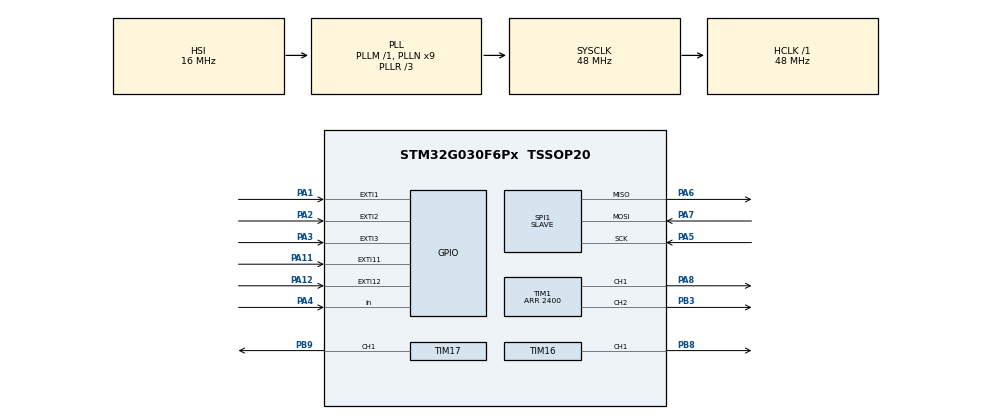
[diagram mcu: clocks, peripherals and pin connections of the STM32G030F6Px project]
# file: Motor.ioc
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Dma.Request0=TIM1_CH1
Dma.Request1=SPI1_RX
Dma.Request2=SPI1_TX
Dma.SPI1_RX.1.Direction=DMA_PERIPH_TO_MEMORY
Dma.SPI1_RX.1.EventEnable=DISABLE
Dma.SPI1_RX.1.Instance=DMA1_Channel1
Dma.SPI1_RX.1.MemDataAlignment=DMA_MDATAALIGN_HALFWORD
Dma.SPI1_RX.1.MemInc=DMA_MINC_ENABLE
Dma.SPI1_RX.1.Mode=DMA_NORMAL
Dma.SPI1_RX.1.PeriphDataAlignment=DMA_PDATAALIGN_HALFWORD
Dma.SPI1_RX.1.PeriphInc=DMA_PINC_DISABLE
Dma.SPI1_RX.1.Polarity=HAL_DMAMUX_REQ_GEN_RISING
Dma.SPI1_RX.1.Priority=DMA_PRIORITY_MEDIUM
Dma.SPI1_RX.1.RequestNumber=1
Dma.SPI1_RX.1.SignalID=NONE
Dma.SPI1_RX.1.SyncEnable=DISABLE
Dma.SPI1_RX.1.SyncPolarity=HAL_DMAMUX_SYNC_NO_EVENT
Dma.SPI1_RX.1.SyncRequestNumber=1
Dma.SPI1_RX.1.SyncSignalID=NONE
Dma.SPI1_TX.2.Direction=DMA_MEMORY_TO_PERIPH
Dma.SPI1_TX.2.EventEnable=DISABLE
Dma.SPI1_TX.2.Instance=DMA1_Channel2
Dma.SPI1_TX.2.MemDataAlignment=DMA_MDATAALIGN_HALFWORD
Dma.SPI1_TX.2.MemInc=DMA_MINC_ENABLE
Dma.SPI1_TX.2.Mode=DMA_NORMAL
Dma.SPI1_TX.2.PeriphDataAlignment=DMA_PDATAALIGN_HALFWORD
Dma.SPI1_TX.2.PeriphInc=DMA_PINC_DISABLE
Dma.SPI1_TX.2.Polarity=HAL_DMAMUX_REQ_GEN_RISING
Dma.SPI1_TX.2.Priority=DMA_PRIORITY_MEDIUM
Dma.SPI1_TX.2.RequestNumber=1
Dma.SPI1_TX.2.SignalID=NONE
Dma.SPI1_TX.2.SyncEnable=DISABLE
Dma.SPI1_TX.2.SyncPolarity=HAL_DMAMUX_SYNC_NO_EVENT
Dma.SPI1_TX.2.SyncRequestNumber=1
Dma.SPI1_TX.2.SyncSignalID=NONE
Dma.TIM1_CH1.0.Direction=DMA_MEMORY_TO_PERIPH
Dma.TIM1_CH1.0.EventEnable=DISABLE
Dma.TIM1_CH1.0.Instance=DMA1_Channel4
Dma.TIM1_CH1.0.MemDataAlignment=DMA_MDATAALIGN_BYTE
Dma.TIM1_CH1.0.MemInc=DMA_MINC_ENABLE
Dma.TIM1_CH1.0.Mode=DMA_CIRCULAR
Dma.TIM1_CH1.0.PeriphDataAlignment=DMA_PDATAALIGN_HALFWORD
Dma.TIM1_CH1.0.PeriphInc=DMA_PINC_DISABLE
Dma.TIM1_CH1.0.Polarity=HAL_DMAMUX_REQ_GEN_RISING
Dma.TIM1_CH1.0.Priority=DMA_PRIORITY_LOW
Dma.TIM1_CH1.0.RequestNumber=1
Dma.TIM1_CH1.0.SignalID=NONE
Dma.TIM1_CH1.0.SyncEnable=DISABLE
Dma.TIM1_CH1.0.SyncPolarity=HAL_DMAMUX_SYNC_NO_EVENT
Dma.TIM1_CH1.0.SyncRequestNumber=1
Dma.TIM1_CH1.0.SyncSignalID=NONE
Mcu.Family=STM32G0
Mcu.Name=STM32G030F6Px
Mcu.Package=TSSOP20
NVIC.DMA1_Ch4_5_DMAMUX1_OVR_IRQn=true\:2\:0\:true\:false\:true\:false\:true\:true
NVIC.DMA1_Channel1_IRQn=true\:0\:0\:true\:false\:true\:false\:true\:true
NVIC.DMA1_Channel2_3_IRQn=true\:0\:0\:true\:false\:true\:false\:true\:true
NVIC.EXTI0_1_IRQn=true\:0\:0\:true\:false\:true\:true\:true\:true
NVIC.EXTI2_3_IRQn=true\:1\:0\:true\:false\:true\:true\:true\:true
NVIC.EXTI4_15_IRQn=true\:1\:0\:true\:false\:true\:true\:true\:true
NVIC.TIM1_BRK_UP_TRG_COM_IRQn=true\:2\:0\:true\:false\:true\:true\:true\:true
NVIC.TIM3_IRQn=true\:3\:0\:true\:false\:true\:true\:true\:true
PA1.Signal=GPXTI1
PA11\ [PA9].Signal=GPXTI11
PA12\ [PA10].Signal=GPXTI12
PA13.Mode=Serial_Wire
PA13.Signal=SYS_SWDIO
PA14-BOOT0.Mode=Serial_Wire
PA14-BOOT0.Signal=SYS_SWCLK
PA14-BOOT0__PA15.StandardMode=true
PA2.Signal=GPXTI2
PA3.Signal=GPXTI3
PA4.Signal=GPIO_Input
PA5.Mode=Full_Duplex_Slave
PA5.Signal=SPI1_SCK
PA6.Mode=Full_Duplex_Slave
PA6.Signal=SPI1_MISO
PA7.Mode=Full_Duplex_Slave
PA7.Signal=SPI1_MOSI
PA8.Signal=S_TIM1_CH1
PB0__PB1__PB2__PA8.StandardMode=true
PB3.Signal=S_TIM1_CH2
PB3__PB4__PB5__PB6.StandardMode=true
PB7__PB8.StandardMode=true
PB8.Signal=S_TIM16_CH1
PB9.Signal=S_TIM17_CH1
PC14-OSC32_IN\ (PC14)__PB9.StandardMode=true
ProjectManager.HeapSize=0x200
ProjectManager.StackSize=0x400
ProjectManager.TargetToolchain=STM32CubeIDE
RCC.ADCFreq_Value=48000000
RCC.AHBFreq_Value=48000000
RCC.CortexFreq_Value=48000000
RCC.EXTERNAL_CLOCK_VALUE=12288000
RCC.HCLKFreq_Value=48000000
RCC.HSE_VALUE=8000000
RCC.HSI_VALUE=16000000
RCC.LSE_VALUE=32768
RCC.PLLN=9
RCC.PLLP=RCC_PLLP_DIV32
RCC.PLLR=RCC_PLLR_DIV3
RCC.SYSCLKFreq_VALUE=48000000
RCC.SYSCLKSource=RCC_SYSCLKSOURCE_PLLCLK
RCC.VCOOutputFreq_Value=144000000
SH.S_TIM16_CH1.0=TIM16_CH1,PWM Generation1 CH1
SH.S_TIM17_CH1.0=TIM17_CH1,PWM Generation1 CH1
SH.S_TIM1_CH1.0=TIM1_CH1,PWM Generation1 CH1
SH.S_TIM1_CH2.0=TIM1_CH2,PWM Generation2 CH2
SPI1.CLKPolarity=SPI_POLARITY_LOW
SPI1.CRCCalculation=SPI_CRCCALCULATION_ENABLE
SPI1.CRCLength=SPI_CRC_LENGTH_DATASIZE
SPI1.DataSize=SPI_DATASIZE_16BIT
SPI1.Direction=SPI_DIRECTION_2LINES
SPI1.Mode=SPI_MODE_SLAVE
SPI1.VirtualType=VM_SLAVE
TIM1.AutoReloadPreload=TIM_AUTORELOAD_PRELOAD_ENABLE
TIM1.Channel-PWM\ Generation1\ CH1=TIM_CHANNEL_1
TIM1.Channel-PWM\ Generation2\ CH2=TIM_CHANNEL_2
TIM1.OCMode_PWM-PWM\ Generation1\ CH1=TIM_OCMODE_PWM1
TIM1.OCPolarity_1=TIM_OCPOLARITY_HIGH
TIM1.OCPolarity_2=TIM_OCPOLARITY_HIGH
TIM1.Period=2400
TIM16.Channel=TIM_CHANNEL_1
TIM16.Period=2400
TIM16.Prescaler=0
TIM17.Channel=TIM_CHANNEL_1
TIM17.Period=2400
TIM17.Prescaler=0
TIM3.AutoReloadPreload=TIM_AUTORELOAD_PRELOAD_ENABLE
TIM3.Period=2400
TIM3.Prescaler=0
TIM3.TIM_MasterOutputTrigger=TIM_TRGO_UPDATE
VP_CRC_VS_CRC.Mode=CRC_Activate
VP_TIM16_VS_ClockSourceINT.Mode=Enable_Timer
VP_TIM17_VS_ClockSourceINT.Mode=Enable_Timer
VP_TIM1_VS_ClockSourceINT.Mode=Internal
VP_TIM3_VS_ClockSourceINT.Mode=Internal
board=custom

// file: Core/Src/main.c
/* USER CODE BEGIN Header */
/**
  ******************************************************************************
  * @file           : main.c
  * @brief          : Main program body
  ******************************************************************************
  * @attention
  *
  * Copyright (c) 2024 STMicroelectronics.
  * All rights reserved.
  *
  * This software is licensed under terms that can be found in the LICENSE file
  * in the root directory of this software component.
  * If no LICENSE file comes with this software, it is provided AS-IS.
  *
  ******************************************************************************
  */
/* USER CODE END Header */
#include "main.h"

/* USER CODE BEGIN PD */
extern void boardInit();
extern void boardLoop();

/* USER CODE END PD */

CRC_HandleTypeDef hcrc;

SPI_HandleTypeDef hspi1;
DMA_HandleTypeDef hdma_spi1_rx;
DMA_HandleTypeDef hdma_spi1_tx;

TIM_HandleTypeDef htim1;
TIM_HandleTypeDef htim3;
TIM_HandleTypeDef htim16;
TIM_HandleTypeDef htim17;
DMA_HandleTypeDef hdma_tim1_ch1;

void SystemClock_Config(void);
static void MX_GPIO_Init(void);
static void MX_DMA_Init(void);
static void MX_SPI1_Init(void);
static void MX_TIM1_Init(void);
static void MX_TIM3_Init(void);
static void MX_CRC_Init(void);
static void MX_TIM16_Init(void);
static void MX_TIM17_Init(void);

int main(void)
{

  /* MCU Configuration--------------------------------------------------------*/

  /* Reset of all peripherals, Initializes the Flash interface and the Systick. */
  HAL_Init();

  /* Configure the system clock */
  SystemClock_Config();

  /* Initialize all configured peripherals */
  MX_GPIO_Init();
  MX_DMA_Init();
  MX_SPI1_Init();
  MX_TIM1_Init();
  MX_TIM3_Init();
  MX_CRC_Init();
  MX_TIM16_Init();
  MX_TIM17_Init();

  /* Infinite loop */
  /* USER CODE BEGIN WHILE */
  boardInit();
  while (1)
  {
    /* USER CODE END WHILE */

    /* USER CODE BEGIN 3 */
    boardLoop();
  }
  /* USER CODE END 3 */
}

void SystemClock_Config(void)
{
  RCC_OscInitTypeDef RCC_OscInitStruct = {0};
  RCC_ClkInitTypeDef RCC_ClkInitStruct = {0};

  /** Configure the main internal regulator output voltage
  */
  HAL_PWREx_ControlVoltageScaling(PWR_REGULATOR_VOLTAGE_SCALE1);

  /** Initializes the RCC Oscillators according to the specified parameters
  * in the RCC_OscInitTypeDef structure.
  */
  RCC_OscInitStruct.OscillatorType = RCC_OSCILLATORTYPE_HSI;
  RCC_OscInitStruct.HSIState = RCC_HSI_ON;
  RCC_OscInitStruct.HSIDiv = RCC_HSI_DIV1;
  RCC_OscInitStruct.HSICalibrationValue = RCC_HSICALIBRATION_DEFAULT;
  RCC_OscInitStruct.PLL.PLLState = RCC_PLL_ON;
  RCC_OscInitStruct.PLL.PLLSource = RCC_PLLSOURCE_HSI;
  RCC_OscInitStruct.PLL.PLLM = RCC_PLLM_DIV1;
  RCC_OscInitStruct.PLL.PLLN = 9;
  RCC_OscInitStruct.PLL.PLLP = RCC_PLLP_DIV32;
  RCC_OscInitStruct.PLL.PLLR = RCC_PLLR_DIV3;
  if (HAL_RCC_OscConfig(&RCC_OscInitStruct) != HAL_OK)
  {
    Error_Handler();
  }

  /** Initializes the CPU, AHB and APB buses clocks
  */
  RCC_ClkInitStruct.ClockType = RCC_CLOCKTYPE_HCLK|RCC_CLOCKTYPE_SYSCLK
                              |RCC_CLOCKTYPE_PCLK1;
  RCC_ClkInitStruct.SYSCLKSource = RCC_SYSCLKSOURCE_PLLCLK;
  RCC_ClkInitStruct.AHBCLKDivider = RCC_SYSCLK_DIV1;
  RCC_ClkInitStruct.APB1CLKDivider = RCC_HCLK_DIV1;

  if (HAL_RCC_ClockConfig(&RCC_ClkInitStruct, FLASH_LATENCY_1) != HAL_OK)
  {
    Error_Handler();
  }
}

static void MX_CRC_Init(void)
{

  hcrc.Instance = CRC;
  hcrc.Init.DefaultPolynomialUse = DEFAULT_POLYNOMIAL_ENABLE;
  hcrc.Init.DefaultInitValueUse = DEFAULT_INIT_VALUE_ENABLE;
  hcrc.Init.InputDataInversionMode = CRC_INPUTDATA_INVERSION_NONE;
  hcrc.Init.OutputDataInversionMode = CRC_OUTPUTDATA_INVERSION_DISABLE;
  hcrc.InputDataFormat = CRC_INPUTDATA_FORMAT_BYTES;
  if (HAL_CRC_Init(&hcrc) != HAL_OK)
  {
    Error_Handler();
  }

}

static void MX_SPI1_Init(void)
{

  /* SPI1 parameter configuration*/
  hspi1.Instance = SPI1;
  hspi1.Init.Mode = SPI_MODE_SLAVE;
  hspi1.Init.Direction = SPI_DIRECTION_2LINES;
  hspi1.Init.DataSize = SPI_DATASIZE_16BIT;
  hspi1.Init.CLKPolarity = SPI_POLARITY_LOW;
  hspi1.Init.CLKPhase = SPI_PHASE_1EDGE;
  hspi1.Init.NSS = SPI_NSS_SOFT;
  hspi1.Init.FirstBit = SPI_FIRSTBIT_MSB;
  hspi1.Init.TIMode = SPI_TIMODE_DISABLE;
  hspi1.Init.CRCCalculation = SPI_CRCCALCULATION_ENABLE;
  hspi1.Init.CRCPolynomial = 7;
  hspi1.Init.CRCLength = SPI_CRC_LENGTH_DATASIZE;
  hspi1.Init.NSSPMode = SPI_NSS_PULSE_DISABLE;
  if (HAL_SPI_Init(&hspi1) != HAL_OK)
  {
    Error_Handler();
  }

}

static void MX_TIM1_Init(void)
{

  TIM_ClockConfigTypeDef sClockSourceConfig = {0};
  TIM_MasterConfigTypeDef sMasterConfig = {0};
  TIM_OC_InitTypeDef sConfigOC = {0};
  TIM_BreakDeadTimeConfigTypeDef sBreakDeadTimeConfig = {0};

  htim1.Instance = TIM1;
  htim1.Init.Prescaler = 0;
  htim1.Init.CounterMode = TIM_COUNTERMODE_UP;
  htim1.Init.Period = 2400;
  htim1.Init.ClockDivision = TIM_CLOCKDIVISION_DIV1;
  htim1.Init.RepetitionCounter = 0;
  htim1.Init.AutoReloadPreload = TIM_AUTORELOAD_PRELOAD_ENABLE;
  if (HAL_TIM_Base_Init(&htim1) != HAL_OK)
  {
    Error_Handler();
  }
  sClockSourceConfig.ClockSource = TIM_CLOCKSOURCE_INTERNAL;
  if (HAL_TIM_ConfigClockSource(&htim1, &sClockSourceConfig) != HAL_OK)
  {
    Error_Handler();
  }
  if (HAL_TIM_PWM_Init(&htim1) != HAL_OK)
  {
    Error_Handler();
  }
  sMasterConfig.MasterOutputTrigger = TIM_TRGO_RESET;
  sMasterConfig.MasterOutputTrigger2 = TIM_TRGO2_RESET;
  sMasterConfig.MasterSlaveMode = TIM_MASTERSLAVEMODE_DISABLE;
  if (HAL_TIMEx_MasterConfigSynchronization(&htim1, &sMasterConfig) != HAL_OK)
  {
    Error_Handler();
  }
  sConfigOC.OCMode = TIM_OCMODE_PWM1;
  sConfigOC.Pulse = 0;
  sConfigOC.OCPolarity = TIM_OCPOLARITY_HIGH;
  sConfigOC.OCNPolarity = TIM_OCNPOLARITY_HIGH;
  sConfigOC.OCFastMode = TIM_OCFAST_DISABLE;
  sConfigOC.OCIdleState = TIM_OCIDLESTATE_RESET;
  sConfigOC.OCNIdleState = TIM_OCNIDLESTATE_RESET;
  if (HAL_TIM_PWM_ConfigChannel(&htim1, &sConfigOC, TIM_CHANNEL_1) != HAL_OK)
  {
    Error_Handler();
  }
  if (HAL_TIM_PWM_ConfigChannel(&htim1, &sConfigOC, TIM_CHANNEL_2) != HAL_OK)
  {
    Error_Handler();
  }
  sBreakDeadTimeConfig.OffStateRunMode = TIM_OSSR_DISABLE;
  sBreakDeadTimeConfig.OffStateIDLEMode = TIM_OSSI_DISABLE;
  sBreakDeadTimeConfig.LockLevel = TIM_LOCKLEVEL_OFF;
  sBreakDeadTimeConfig.DeadTime = 0;
  sBreakDeadTimeConfig.BreakState = TIM_BREAK_DISABLE;
  sBreakDeadTimeConfig.BreakPolarity = TIM_BREAKPOLARITY_HIGH;
  sBreakDeadTimeConfig.BreakFilter = 0;
  sBreakDeadTimeConfig.BreakAFMode = TIM_BREAK_AFMODE_INPUT;
  sBreakDeadTimeConfig.Break2State = TIM_BREAK2_DISABLE;
  sBreakDeadTimeConfig.Break2Polarity = TIM_BREAK2POLARITY_HIGH;
  sBreakDeadTimeConfig.Break2Filter = 0;
  sBreakDeadTimeConfig.Break2AFMode = TIM_BREAK_AFMODE_INPUT;
  sBreakDeadTimeConfig.AutomaticOutput = TIM_AUTOMATICOUTPUT_DISABLE;
  if (HAL_TIMEx_ConfigBreakDeadTime(&htim1, &sBreakDeadTimeConfig) != HAL_OK)
  {
    Error_Handler();
  }
  HAL_TIM_MspPostInit(&htim1);

}

static void MX_TIM3_Init(void)
{

  TIM_ClockConfigTypeDef sClockSourceConfig = {0};
  TIM_MasterConfigTypeDef sMasterConfig = {0};

  htim3.Instance = TIM3;
  htim3.Init.Prescaler = 0;
  htim3.Init.CounterMode = TIM_COUNTERMODE_UP;
  htim3.Init.Period = 2400;
  htim3.Init.ClockDivision = TIM_CLOCKDIVISION_DIV1;
  htim3.Init.AutoReloadPreload = TIM_AUTORELOAD_PRELOAD_ENABLE;
  if (HAL_TIM_Base_Init(&htim3) != HAL_OK)
  {
    Error_Handler();
  }
  sClockSourceConfig.ClockSource = TIM_CLOCKSOURCE_INTERNAL;
  if (HAL_TIM_ConfigClockSource(&htim3, &sClockSourceConfig) != HAL_OK)
  {
    Error_Handler();
  }
  sMasterConfig.MasterOutputTrigger = TIM_TRGO_UPDATE;
  sMasterConfig.MasterSlaveMode = TIM_MASTERSLAVEMODE_DISABLE;
  if (HAL_TIMEx_MasterConfigSynchronization(&htim3, &sMasterConfig) != HAL_OK)
  {
    Error_Handler();
  }

}

static void MX_TIM16_Init(void)
{

  TIM_OC_InitTypeDef sConfigOC = {0};
  TIM_BreakDeadTimeConfigTypeDef sBreakDeadTimeConfig = {0};

  htim16.Instance = TIM16;
  htim16.Init.Prescaler = 0;
  htim16.Init.CounterMode = TIM_COUNTERMODE_UP;
  htim16.Init.Period = 2400;
  htim16.Init.ClockDivision = TIM_CLOCKDIVISION_DIV1;
  htim16.Init.RepetitionCounter = 0;
  htim16.Init.AutoReloadPreload = TIM_AUTORELOAD_PRELOAD_DISABLE;
  if (HAL_TIM_Base_Init(&htim16) != HAL_OK)
  {
    Error_Handler();
  }
  if (HAL_TIM_PWM_Init(&htim16) != HAL_OK)
  {
    Error_Handler();
  }
  sConfigOC.OCMode = TIM_OCMODE_PWM1;
  sConfigOC.Pulse = 0;
  sConfigOC.OCPolarity = TIM_OCPOLARITY_HIGH;
  sConfigOC.OCNPolarity = TIM_OCNPOLARITY_HIGH;
  sConfigOC.OCFastMode = TIM_OCFAST_DISABLE;
  sConfigOC.OCIdleState = TIM_OCIDLESTATE_RESET;
  sConfigOC.OCNIdleState = TIM_OCNIDLESTATE_RESET;
  if (HAL_TIM_PWM_ConfigChannel(&htim16, &sConfigOC, TIM_CHANNEL_1) != HAL_OK)
  {
    Error_Handler();
  }
  sBreakDeadTimeConfig.OffStateRunMode = TIM_OSSR_DISABLE;
  sBreakDeadTimeConfig.OffStateIDLEMode = TIM_OSSI_DISABLE;
  sBreakDeadTimeConfig.LockLevel = TIM_LOCKLEVEL_OFF;
  sBreakDeadTimeConfig.DeadTime = 0;
  sBreakDeadTimeConfig.BreakState = TIM_BREAK_DISABLE;
  sBreakDeadTimeConfig.BreakPolarity = TIM_BREAKPOLARITY_HIGH;
  sBreakDeadTimeConfig.BreakFilter = 0;
  sBreakDeadTimeConfig.AutomaticOutput = TIM_AUTOMATICOUTPUT_DISABLE;
  if (HAL_TIMEx_ConfigBreakDeadTime(&htim16, &sBreakDeadTimeConfig) != HAL_OK)
  {
    Error_Handler();
  }
  HAL_TIM_MspPostInit(&htim16);

}

static void MX_TIM17_Init(void)
{

  TIM_OC_InitTypeDef sConfigOC = {0};
  TIM_BreakDeadTimeConfigTypeDef sBreakDeadTimeConfig = {0};

  htim17.Instance = TIM17;
  htim17.Init.Prescaler = 0;
  htim17.Init.CounterMode = TIM_COUNTERMODE_UP;
  htim17.Init.Period = 2400;
  htim17.Init.ClockDivision = TIM_CLOCKDIVISION_DIV1;
  htim17.Init.RepetitionCounter = 0;
  htim17.Init.AutoReloadPreload = TIM_AUTORELOAD_PRELOAD_DISABLE;
  if (HAL_TIM_Base_Init(&htim17) != HAL_OK)
  {
    Error_Handler();
  }
  if (HAL_TIM_PWM_Init(&htim17) != HAL_OK)
  {
    Error_Handler();
  }
  sConfigOC.OCMode = TIM_OCMODE_PWM1;
  sConfigOC.Pulse = 0;
  sConfigOC.OCPolarity = TIM_OCPOLARITY_HIGH;
  sConfigOC.OCNPolarity = TIM_OCNPOLARITY_HIGH;
  sConfigOC.OCFastMode = TIM_OCFAST_DISABLE;
  sConfigOC.OCIdleState = TIM_OCIDLESTATE_RESET;
  sConfigOC.OCNIdleState = TIM_OCNIDLESTATE_RESET;
  if (HAL_TIM_PWM_ConfigChannel(&htim17, &sConfigOC, TIM_CHANNEL_1) != HAL_OK)
  {
    Error_Handler();
  }
  sBreakDeadTimeConfig.OffStateRunMode = TIM_OSSR_DISABLE;
  sBreakDeadTimeConfig.OffStateIDLEMode = TIM_OSSI_DISABLE;
  sBreakDeadTimeConfig.LockLevel = TIM_LOCKLEVEL_OFF;
  sBreakDeadTimeConfig.DeadTime = 0;
  sBreakDeadTimeConfig.BreakState = TIM_BREAK_DISABLE;
  sBreakDeadTimeConfig.BreakPolarity = TIM_BREAKPOLARITY_HIGH;
  sBreakDeadTimeConfig.BreakFilter = 0;
  sBreakDeadTimeConfig.AutomaticOutput = TIM_AUTOMATICOUTPUT_DISABLE;
  if (HAL_TIMEx_ConfigBreakDeadTime(&htim17, &sBreakDeadTimeConfig) != HAL_OK)
  {
    Error_Handler();
  }
  HAL_TIM_MspPostInit(&htim17);

}

static void MX_DMA_Init(void)
{

  /* DMA controller clock enable */
  __HAL_RCC_DMA1_CLK_ENABLE();

  /* DMA interrupt init */
  /* DMA1_Channel1_IRQn interrupt configuration */
  HAL_NVIC_SetPriority(DMA1_Channel1_IRQn, 0, 0);
  HAL_NVIC_EnableIRQ(DMA1_Channel1_IRQn);
  /* DMA1_Channel2_3_IRQn interrupt configuration */
  HAL_NVIC_SetPriority(DMA1_Channel2_3_IRQn, 0, 0);
  HAL_NVIC_EnableIRQ(DMA1_Channel2_3_IRQn);
  /* DMA1_Ch4_5_DMAMUX1_OVR_IRQn interrupt configuration */
  HAL_NVIC_SetPriority(DMA1_Ch4_5_DMAMUX1_OVR_IRQn, 2, 0);
  HAL_NVIC_EnableIRQ(DMA1_Ch4_5_DMAMUX1_OVR_IRQn);

}

static void MX_GPIO_Init(void)
{
  GPIO_InitTypeDef GPIO_InitStruct = {0};

  /* GPIO Ports Clock Enable */
  __HAL_RCC_GPIOB_CLK_ENABLE();
  __HAL_RCC_GPIOA_CLK_ENABLE();

  /*Configure GPIO pins : PA1 PA2 PA3 PA11
                           PA12 */
  GPIO_InitStruct.Pin = GPIO_PIN_1|GPIO_PIN_2|GPIO_PIN_3|GPIO_PIN_11
                          |GPIO_PIN_12;
  GPIO_InitStruct.Mode = GPIO_MODE_IT_RISING;
  GPIO_InitStruct.Pull = GPIO_NOPULL;
  HAL_GPIO_Init(GPIOA, &GPIO_InitStruct);

  /*Configure GPIO pin : PA4 */
  GPIO_InitStruct.Pin = GPIO_PIN_4;
  GPIO_InitStruct.Mode = GPIO_MODE_INPUT;
  GPIO_InitStruct.Pull = GPIO_NOPULL;
  HAL_GPIO_Init(GPIOA, &GPIO_InitStruct);

  /* EXTI interrupt init*/
  HAL_NVIC_SetPriority(EXTI0_1_IRQn, 0, 0);
  HAL_NVIC_EnableIRQ(EXTI0_1_IRQn);

  HAL_NVIC_SetPriority(EXTI2_3_IRQn, 1, 0);
  HAL_NVIC_EnableIRQ(EXTI2_3_IRQn);

  HAL_NVIC_SetPriority(EXTI4_15_IRQn, 1, 0);
  HAL_NVIC_EnableIRQ(EXTI4_15_IRQn);

}

void Error_Handler(void)
{
  __disable_irq();
  while (1)
  {
  }
}
